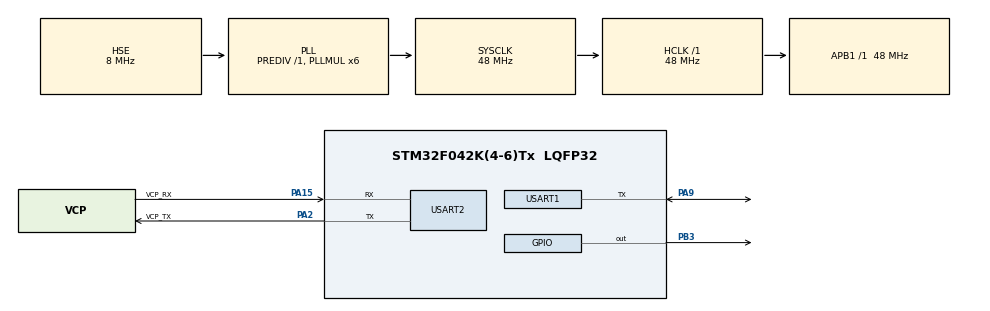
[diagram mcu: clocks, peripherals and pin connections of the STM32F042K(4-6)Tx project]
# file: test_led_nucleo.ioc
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Mcu.Family=STM32F0
Mcu.Name=STM32F042K(4-6)Tx
Mcu.Package=LQFP32
NVIC.USART1_IRQn=true\:0\:0\:false\:false\:true\:true\:true
PA13.GPIO_Label=SWDIO
PA13.Mode=Serial_Wire
PA13.Signal=SYS_SWDIO
PA14.Mode=Serial_Wire
PA14.Signal=SYS_SWCLK
PA15.GPIO_Label=VCP_RX
PA15.Mode=Asynchronous
PA15.Signal=USART2_RX
PA2.GPIO_Label=VCP_TX
PA2.Mode=Asynchronous
PA2.Signal=USART2_TX
PA9.Mode=Half_duplex(single_wire_mode)
PA9.Signal=USART1_TX
PB3.Signal=GPIO_Output
PF0-OSC_IN.GPIO_Label=MCO
PF0-OSC_IN.Mode=HSE-External-Oscillator
PF0-OSC_IN.Signal=RCC_OSC_IN
PF1-OSC_OUT.Mode=HSE-External-Oscillator
PF1-OSC_OUT.Signal=RCC_OSC_OUT
ProjectManager.HeapSize=0x200
ProjectManager.StackSize=0x400
ProjectManager.TargetToolchain=Makefile
RCC.AHBFreq_Value=48000000
RCC.APB1Freq_Value=48000000
RCC.APB1TimFreq_Value=48000000
RCC.HCLKFreq_Value=48000000
RCC.PLLMUL=RCC_PLL_MUL6
RCC.PLLSourceVirtual=RCC_PLLSOURCE_HSE
RCC.SYSCLKFreq_VALUE=48000000
RCC.SYSCLKSource=RCC_SYSCLKSOURCE_PLLCLK
USART1.BaudRate=115200
USART1.VirtualMode-Half_duplex(single_wire_mode)=VM_ASYNC
USART2.VirtualMode-Asynchronous=VM_ASYNC
board=NUCLEO-F042K6

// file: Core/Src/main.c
/* USER CODE BEGIN Header */
/**
  ******************************************************************************
  * @file           : main.c
  * @brief          : Main program body
  ******************************************************************************
  * @attention
  *
  * <h2><center>&copy; Copyright (c) 2021 STMicroelectronics.
  * All rights reserved.</center></h2>
  *
  * This software component is licensed by ST under BSD 3-Clause license,
  * the "License"; You may not use this file except in compliance with the
  * License. You may obtain a copy of the License at:
  *                        opensource.org/licenses/BSD-3-Clause
  *
  ******************************************************************************
  */
/* USER CODE END Header */
#include "main.h"
#include "usart.h"
#include "gpio.h"

/* USER CODE BEGIN Includes */
#include "stdio.h"
/* USER CODE END Includes */

void SystemClock_Config(void);

/* USER CODE BEGIN 0 */
/// Write syscall for printf
int _write(int fd, unsigned char *ptr, int len)
{
	if (HAL_UART_Transmit(&huart2, ptr, len, HAL_MAX_DELAY) != HAL_OK)
		return 0;

	return len;
}
void assert(const char *code, const char *file, const unsigned line, const int res)
{
	if (res  == 0)
	{
		printf("\rassertion \"%s\" failed: file \"%s\", line %d\n", code, file, line);
		while (1);
	}
}

/* USER CODE END 0 */

int main(void)
{

  /* MCU Configuration--------------------------------------------------------*/

  /* Reset of all peripherals, Initializes the Flash interface and the Systick. */
  HAL_Init();

  /* Configure the system clock */
  SystemClock_Config();

  /* Initialize all configured peripherals */
  MX_GPIO_Init();
  MX_USART2_UART_Init();
  MX_USART1_UART_Init();
  /* USER CODE BEGIN 2 */

  //LobotSerialServoMove(&huart1,1,1000,1000);
 //printf("ping=%i\n\r",pingServo(8));

  //HAL_GPIO_WritePin(GPIOB,GPIO_PIN_3,1);
  /* USER CODE END 2 */

  /* Infinite loop */
  /* USER CODE BEGIN WHILE */
  while (1)
  {
// if(pingServo(8))
// {HAL_GPIO_WritePin(GPIOB,GPIO_PIN_3,1);}
//printf("ping=%i\n\r",pingServo(8));

//   HAL_Delay(100);
    /* USER CODE END WHILE */

  }
}

void SystemClock_Config(void)
{
  RCC_OscInitTypeDef RCC_OscInitStruct = {0};
  RCC_ClkInitTypeDef RCC_ClkInitStruct = {0};
  RCC_PeriphCLKInitTypeDef PeriphClkInit = {0};

  /** Initializes the RCC Oscillators according to the specified parameters
  * in the RCC_OscInitTypeDef structure.
  */
  RCC_OscInitStruct.OscillatorType = RCC_OSCILLATORTYPE_HSE;
  RCC_OscInitStruct.HSEState = RCC_HSE_ON;
  RCC_OscInitStruct.PLL.PLLState = RCC_PLL_ON;
  RCC_OscInitStruct.PLL.PLLSource = RCC_PLLSOURCE_HSE;
  RCC_OscInitStruct.PLL.PLLMUL = RCC_PLL_MUL6;
  RCC_OscInitStruct.PLL.PREDIV = RCC_PREDIV_DIV1;
  if (HAL_RCC_OscConfig(&RCC_OscInitStruct) != HAL_OK)
  {
   // Error_Handler();
  }
  /** Initializes the CPU, AHB and APB buses clocks
  */
  RCC_ClkInitStruct.ClockType = RCC_CLOCKTYPE_HCLK|RCC_CLOCKTYPE_SYSCLK
                              |RCC_CLOCKTYPE_PCLK1;
  RCC_ClkInitStruct.SYSCLKSource = RCC_SYSCLKSOURCE_PLLCLK;
  RCC_ClkInitStruct.AHBCLKDivider = RCC_SYSCLK_DIV1;
  RCC_ClkInitStruct.APB1CLKDivider = RCC_HCLK_DIV1;

  if (HAL_RCC_ClockConfig(&RCC_ClkInitStruct, FLASH_LATENCY_1) != HAL_OK)
  {
   // Error_Handler();
  }
  PeriphClkInit.PeriphClockSelection = RCC_PERIPHCLK_USART1;
  PeriphClkInit.Usart1ClockSelection = RCC_USART1CLKSOURCE_PCLK1;
  if (HAL_RCCEx_PeriphCLKConfig(&PeriphClkInit) != HAL_OK)
  {
    //Error_Handler();
  }
}

void Error_Handler(void)
{
  /* USER CODE BEGIN Error_Handler_Debug */
   // HAL_GPIO_WritePin(GPIOB,GPIO_PIN_3,1);

  /* User can add his own implementation to report the HAL error return state */
  __disable_irq();
  while (1)
  {
  }
  /* USER CODE END Error_Handler_Debug */
}

/************************ (C) COPYRIGHT STMicroelectronics *****END OF FILE****/
